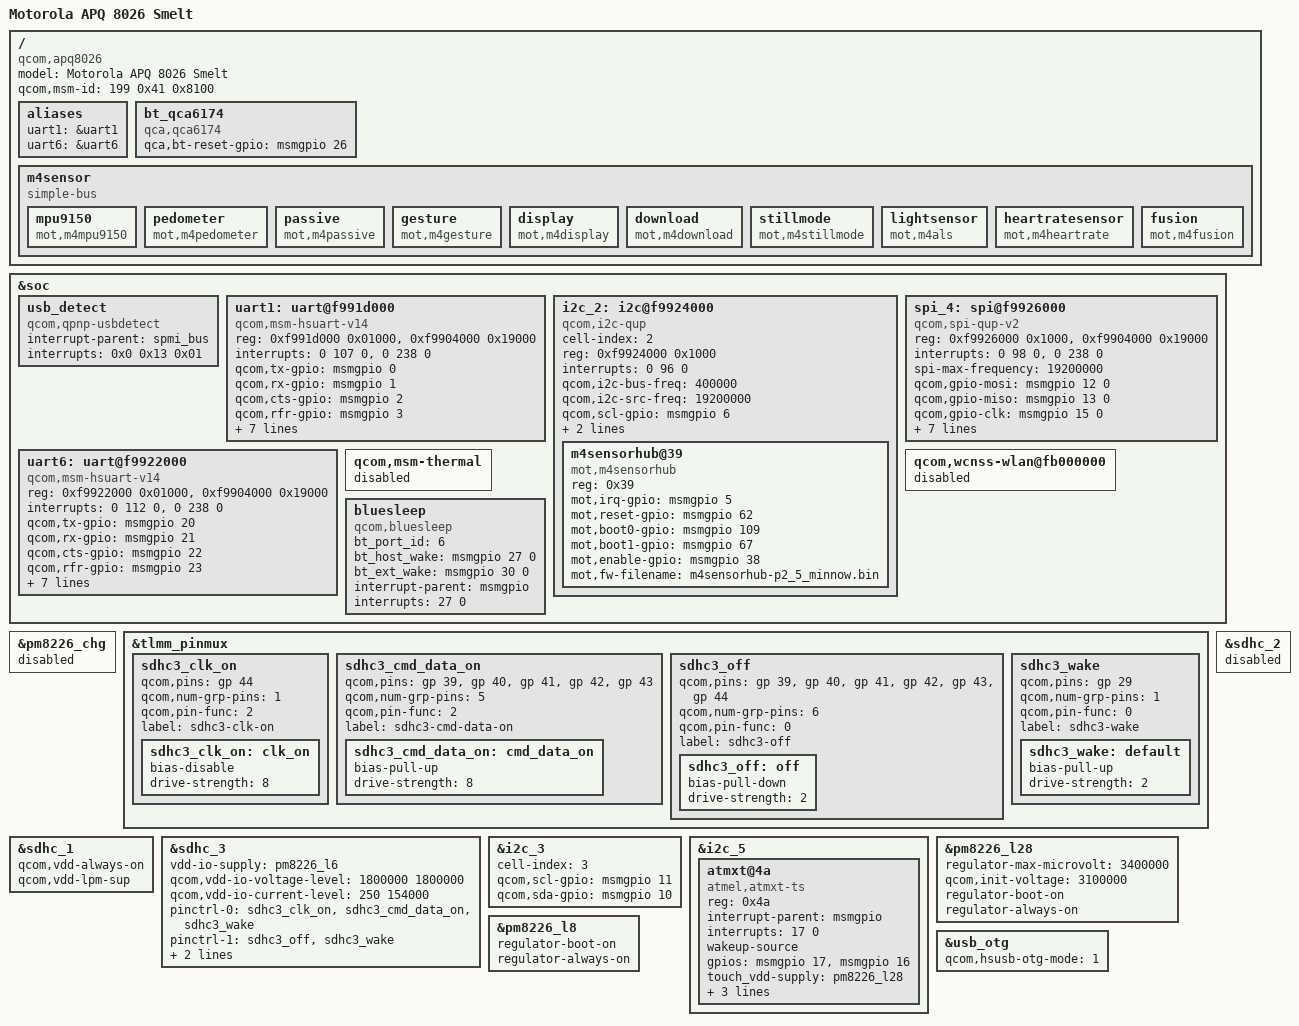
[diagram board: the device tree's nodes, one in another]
/* Copyright (c) 2014, The Linux Foundation. All rights reserved.
 *
 * This program is free software; you can redistribute it and/or modify
 * it under the terms of the GNU General Public License version 2 and
 * only version 2 as published by the Free Software Foundation.
 *
 * This program is distributed in the hope that it will be useful,
 * but WITHOUT ANY WARRANTY; without even the implied warranty of
 * MERCHANTABILITY or FITNESS FOR A PARTICULAR PURPOSE.  See the
 * GNU General Public License for more details.
 */

/dts-v1/;
#include "qcom/msm8226-v1.dtsi"
#include "qcom/msm8226-memory.dtsi"
#include "qcom/msm8226-qseecom.dtsi"
#include "qcom/msm8226-720p-mtp.dtsi"

/ {
	model = "Motorola APQ 8026 Smelt";
	compatible = "qcom,apq8026", "qcom,msm8226", "qcom,mtp", "moto,smelt";
	/* TODO: fix these values */
	qcom,msm-id = <199 0x41 0x8100>;

	aliases {
		/delete-property/ spi0;
		uart1 = &uart1;
		uart6 = &uart6;
	};

	bt_qca6174 {
		compatible = "qca,qca6174";
		qca,bt-reset-gpio = <&msmgpio 26 0>; /* BT_ENABLE */
	};

	m4sensor {
		compatible = "simple-bus";

		mpu9150 {
			compatible = "mot,m4mpu9150";
		};
		pedometer {
			compatible = "mot,m4pedometer";
		};
		passive {
			compatible = "mot,m4passive";
		};
		gesture {
			compatible = "mot,m4gesture";
		};
		display {
			compatible = "mot,m4display";
		};
		download {
			compatible = "mot,m4download";
		};
		stillmode {
			compatible = "mot,m4stillmode";
		};
		lightsensor {
			compatible = "mot,m4als";
		};
		heartratesensor {
			compatible = "mot,m4heartrate";
		};
		fusion {
			compatible = "mot,m4fusion";
		};
	};
};

&soc {
	usb_detect {
		compatible = "qcom,qpnp-usbdetect";
		interrupt-parent = <&spmi_bus>;
		interrupts = <0x0 0x13 0x01>;
		interrupt-names = "vbus_det_irq";
	};

	/* BLSP1: UART */
	/delete-node/ spi@f9923000;
	uart1: uart@f991d000 { /* BLSP1 UART1 */
		compatible = "qcom,msm-hsuart-v14";
		reg = <0xf991d000 0x01000>,
		      <0xf9904000 0x19000>;
		reg-names = "core_mem", "bam_mem";
		interrupts = <0 107 0>, <0 238 0>;
		interrupt-names = "core_irq", "bam_irq";

		qcom,tx-gpio = <&msmgpio 0 0x00>;
		qcom,rx-gpio = <&msmgpio 1 0x00>;
		qcom,cts-gpio = <&msmgpio 2 0x00>;
		qcom,rfr-gpio = <&msmgpio 3 0x00>;

		qcom,bam-tx-ep-pipe-index = <0>; /* BAM Consumer Pipe */
		qcom,bam-rx-ep-pipe-index = <1>; /* BAM Producer Pipe */
		qcom,msm-bus,name = "uart1";
		qcom,msm-bus,num-cases = <2>;
		qcom,msm-bus,num-paths = <1>;

		qcom,msm-bus,vectors-KBps =
			<86 512 0 0>,
			<86 512 500 800>;
	};

	/* BLSP2: I2C */
	i2c_2: i2c@f9924000 { /* BLSP-1 QUP-2 */
		cell-index = <2>;
		compatible = "qcom,i2c-qup";
		reg = <0xf9924000 0x1000>;
		#address-cells = <1>;
		#size-cells = <0>;
		reg-names = "qup_phys_addr";
		interrupts = <0 96 0>;
		interrupt-names = "qup_err_intr";
		qcom,i2c-bus-freq = <400000>;
		qcom,i2c-src-freq = <19200000>;
		qcom,scl-gpio = <&msmgpio 6 0>;
		qcom,sda-gpio = <&msmgpio 7 0>;
		qcom,master-id = <86>;
	};

	/* BLSP4: [spi_4] (C55) */
	/delete-node/ i2c@f9926000;
	spi_4: spi@f9926000 { /* BLSP1 SPI4 */
		compatible = "qcom,spi-qup-v2";
		#address-cells = <1>;
		#size-cells = <0>;
		reg-names = "spi_physical", "spi_bam_physical";
		reg = <0xf9926000 0x1000>,
		      <0xf9904000 0x19000>;
		interrupt-names = "spi_irq", "spi_bam_irq";
		interrupts = <0 98 0>, <0 238 0>;
		spi-max-frequency = <19200000>;

		qcom,gpio-mosi = <&msmgpio 12 0>;
		qcom,gpio-miso = <&msmgpio 13 0>;
		qcom,gpio-clk  = <&msmgpio 15 0>;
		qcom,gpio-cs0  = <&msmgpio 14 0>;

		qcom,infinite-mode = <0>;
		qcom,use-bam;
		qcom,ver-reg-exists;
		qcom,bam-consumer-pipe-index = <18>;
		qcom,bam-producer-pipe-index = <19>;
		qcom,master-id = <86>;
	};

	/* BLSP6: [uart] BT */
	uart6: uart@f9922000 { /* BLSP1 UART6 */
		compatible = "qcom,msm-hsuart-v14";
		reg = <0xf9922000 0x01000>,
		      <0xf9904000 0x19000>;
		reg-names = "core_mem", "bam_mem";
		interrupts = <0 112 0>, <0 238 0>;
		interrupt-names = "core_irq", "bam_irq";

		qcom,tx-gpio = <&msmgpio 20 0x00>;
		qcom,rx-gpio = <&msmgpio 21 0x00>;
		qcom,cts-gpio = <&msmgpio 22 0x00>;
		qcom,rfr-gpio = <&msmgpio 23 0x00>;

		qcom,bam-tx-ep-pipe-index = <10>; /* BAM Consumer Pipe */
		qcom,bam-rx-ep-pipe-index = <11>; /* BAM Producer Pipe */
		qcom,msm-bus,name = "uart6";
		qcom,msm-bus,num-cases = <2>;
		qcom,msm-bus,num-paths = <1>;

		qcom,msm-bus,vectors-KBps =
			<86 512 0 0>,
			<86 512 500 800>;
	};

	qcom,msm-thermal {
		status = "disabled";
	};

	qcom,wcnss-wlan@fb000000 {
		status = "disabled";
	};

	bluesleep {
		compatible = "qcom,bluesleep";
		bt_port_id = <6>;
		bt_host_wake = <&msmgpio 27 0>;
		bt_ext_wake = <&msmgpio 30 0>;
		interrupt-parent = <&msmgpio>;
		interrupts = <27 0>;
		interrupt-names = "host_wake";
	};
};

&pm8226_chg {
	status = "disabled";
};

&tlmm_pinmux {
	sdhc3_clk_on {
		qcom,pins = <&gp 44>;
		qcom,num-grp-pins = <1>;
		qcom,pin-func = <2>;
		label = "sdhc3-clk-on";
		sdhc3_clk_on: clk_on {
			bias-disable;
			drive-strength = <8>;
		};
	};

	sdhc3_cmd_data_on {
		qcom,pins = <&gp 39 &gp 40 &gp 41 &gp 42 &gp 43>;
		qcom,num-grp-pins = <5>;
		qcom,pin-func = <2>;
		label = "sdhc3-cmd-data-on";
		sdhc3_cmd_data_on: cmd_data_on {
			bias-pull-up;
			drive-strength = <8>;
		};
	};

	sdhc3_off {
		qcom,pins = <&gp 39 &gp 40 &gp 41 &gp 42 &gp 43 &gp 44>;
		qcom,num-grp-pins = <6>;
		qcom,pin-func = <0>;
		label = "sdhc3-off";
		sdhc3_off: off {
			bias-pull-down;
			drive-strength = <2>;
		};
	};

	sdhc3_wake {
		qcom,pins = <&gp 29>;
		qcom,num-grp-pins = <1>;
		qcom,pin-func = <0>;
		label = "sdhc3-wake";
		sdhc3_wake: default {
			bias-pull-up;
			drive-strength = <2>;
		};
	};
};

&sdhc_1 {
	qcom,vdd-always-on;
	qcom,vdd-lpm-sup;
};

&sdhc_2 {
	status = "disabled";
};

&sdhc_3 {
	vdd-io-supply = <&pm8226_l6>;
	qcom,vdd-io-voltage-level = <1800000 1800000>;
	qcom,vdd-io-current-level = <250 154000>;

	pinctrl-names = "active", "sleep";
	pinctrl-0 = <&sdhc3_clk_on &sdhc3_cmd_data_on &sdhc3_wake>;
	pinctrl-1 = <&sdhc3_off &sdhc3_wake>;

	interrupt-map = <0 &intc 0 127 0
			 1 &intc 0 224 0
			 2 &msmgpio 29 0x8>;

	status = "ok";
};

&i2c_2 {
	status = "ok";
		m4sensorhub@39 {
		compatible = "mot,m4sensorhub";
		status = "ok";

		reg = <0x39>;
		mot,irq-gpio    = <&msmgpio 5 0x00>;
		mot,reset-gpio  = <&msmgpio 62 0x00>;
		mot,boot0-gpio  = <&msmgpio 109 0x00>;
		mot,boot1-gpio  = <&msmgpio 67 0x00>;
		mot,enable-gpio = <&msmgpio 38 0x00>;
		mot,fw-filename = "m4sensorhub-p2_5_minnow.bin";
	};
};

&i2c_3 {
	cell-index = <3>;
	qcom,scl-gpio = <&msmgpio 11 0>;
	qcom,sda-gpio = <&msmgpio 10 0>;
	status = "ok";
	/* drivers here */
};

&i2c_5 {
	status = "ok";
	/* drivers here */
	atmxt@4a {
		compatible = "atmel,atmxt-ts";
		reg = <0x4a>;
		interrupt-parent = <&msmgpio>;
		interrupts = <17 0>;
		wakeup-source;
		gpios = <&msmgpio 17 0>, /* IRQ */
			<&msmgpio 16 0>; /* RESET */
		touch_vdd-supply = <&pm8226_l28>;
		atmel,atmxt-tdat-filename = "atmxt-r2.tdat", "atmxt-r3.tdat";
		support-snowflake = <1>;
	};
};

&pm8226_l28 {
        regulator-max-microvolt = <3400000>;
        qcom,init-voltage = <3100000>;
        regulator-boot-on;
        regulator-always-on;
};

&pm8226_l8 {
        regulator-boot-on;
        regulator-always-on;
};


&spi_4 {
	status = "ok";
};

&uart1 {
	status = "ok";
};

&uart6 {
	status = "ok";
};

&usb_otg {
	qcom,hsusb-otg-mode = <1>;         /* USB_PERIPHERAL           */
};
